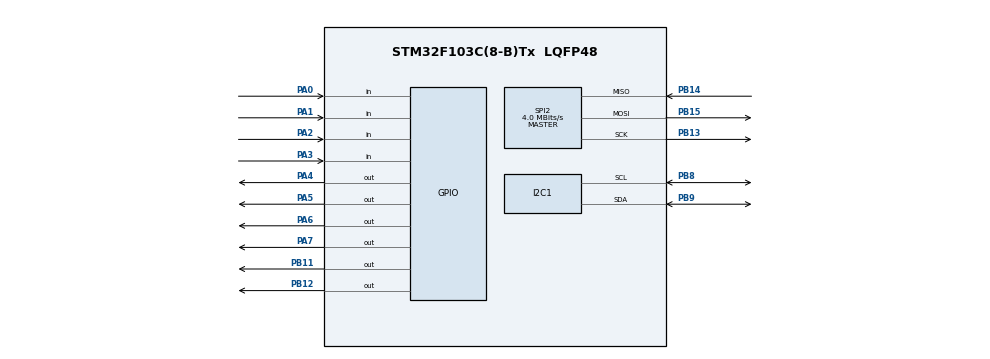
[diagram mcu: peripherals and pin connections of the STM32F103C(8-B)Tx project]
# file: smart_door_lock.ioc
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Mcu.Family=STM32F1
Mcu.Name=STM32F103C(8-B)Tx
Mcu.Package=LQFP48
NVIC.PriorityGroup=NVIC_PRIORITYGROUP_4
PA0-WKUP.GPIO_PuPd=GPIO_PULLUP
PA0-WKUP.Signal=GPIO_Input
PA1.GPIO_PuPd=GPIO_PULLUP
PA1.Signal=GPIO_Input
PA13.Mode=Serial_Wire
PA13.Signal=SYS_JTMS-SWDIO
PA14.Mode=Serial_Wire
PA14.Signal=SYS_JTCK-SWCLK
PA2.GPIO_PuPd=GPIO_PULLUP
PA2.Signal=GPIO_Input
PA3.GPIO_PuPd=GPIO_PULLUP
PA3.Signal=GPIO_Input
PA4.GPIO_PuPd=GPIO_PULLUP
PA4.Signal=GPIO_Output
PA5.GPIO_PuPd=GPIO_PULLUP
PA5.Signal=GPIO_Output
PA6.GPIO_PuPd=GPIO_PULLUP
PA6.Signal=GPIO_Output
PA7.GPIO_PuPd=GPIO_PULLUP
PA7.Signal=GPIO_Output
PB11.GPIO_PuPd=GPIO_PULLUP
PB11.Signal=GPIO_Output
PB12.Signal=GPIO_Output
PB13.Mode=Full_Duplex_Master
PB13.Signal=SPI2_SCK
PB14.Mode=Full_Duplex_Master
PB14.Signal=SPI2_MISO
PB15.Mode=Full_Duplex_Master
PB15.Signal=SPI2_MOSI
PB8.Mode=I2C
PB8.Signal=I2C1_SCL
PB9.Mode=I2C
PB9.Signal=I2C1_SDA
PD0-OSC_IN.Mode=HSE-External-Oscillator
PD0-OSC_IN.Signal=RCC_OSC_IN
PD1-OSC_OUT.Mode=HSE-External-Oscillator
PD1-OSC_OUT.Signal=RCC_OSC_OUT
ProjectManager.HeapSize=0x200
ProjectManager.StackSize=0x400
ProjectManager.TargetToolchain=STM32CubeIDE
RCC.APB1Freq_Value=8000000
RCC.APB2Freq_Value=8000000
SPI2.BaudRatePrescaler=SPI_BAUDRATEPRESCALER_2
SPI2.CLKPhase=SPI_PHASE_2EDGE
SPI2.CLKPolarity=SPI_POLARITY_HIGH
SPI2.CRCCalculation=SPI_CRCCALCULATION_DISABLE
SPI2.CalculateBaudRate=4.0 MBits/s
SPI2.DataSize=SPI_DATASIZE_8BIT
SPI2.Direction=SPI_DIRECTION_2LINES
SPI2.Mode=SPI_MODE_MASTER
SPI2.VirtualType=VM_MASTER
board=custom

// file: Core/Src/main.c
/* USER CODE BEGIN Header */
/**
  ******************************************************************************
  * @file           : main.c
  * @brief          : Main program body
  ******************************************************************************
  * @attention
  *
  * Copyright (c) 2023 STMicroelectronics.
  * All rights reserved.
  *
  * This software is licensed under terms that can be found in the LICENSE file
  * in the root directory of this software component.
  * If no LICENSE file comes with this software, it is provided AS-IS.
  *
  ******************************************************************************
  */
/* USER CODE END Header */
#include "main.h"

/* USER CODE BEGIN Includes */
#include "application.h"
/* USER CODE END Includes */

I2C_HandleTypeDef hi2c1;

SPI_HandleTypeDef hspi2;

void SystemClock_Config(void);
static void MX_GPIO_Init(void);
static void MX_SPI2_Init(void);
static void MX_I2C1_Init(void);

int main(void)
{

  /* MCU Configuration--------------------------------------------------------*/

  /* Reset of all peripherals, Initializes the Flash interface and the Systick. */
  HAL_Init();

  /* Configure the system clock */
  SystemClock_Config();

  /* Initialize all configured peripherals */
  MX_GPIO_Init();
  MX_SPI2_Init();
  MX_I2C1_Init();

  /* Infinite loop */
  while (1)
  {

    /* USER CODE BEGIN 3 */
	 app_loop(&hspi2, &hi2c1);
  }
  /* USER CODE END 3 */
}

void SystemClock_Config(void)
{
  RCC_OscInitTypeDef RCC_OscInitStruct = {0};
  RCC_ClkInitTypeDef RCC_ClkInitStruct = {0};

  /** Initializes the RCC Oscillators according to the specified parameters
  * in the RCC_OscInitTypeDef structure.
  */
  RCC_OscInitStruct.OscillatorType = RCC_OSCILLATORTYPE_HSI;
  RCC_OscInitStruct.HSIState = RCC_HSI_ON;
  RCC_OscInitStruct.HSICalibrationValue = RCC_HSICALIBRATION_DEFAULT;
  RCC_OscInitStruct.PLL.PLLState = RCC_PLL_NONE;
  if (HAL_RCC_OscConfig(&RCC_OscInitStruct) != HAL_OK)
  {
    Error_Handler();
  }

  /** Initializes the CPU, AHB and APB buses clocks
  */
  RCC_ClkInitStruct.ClockType = RCC_CLOCKTYPE_HCLK|RCC_CLOCKTYPE_SYSCLK
                              |RCC_CLOCKTYPE_PCLK1|RCC_CLOCKTYPE_PCLK2;
  RCC_ClkInitStruct.SYSCLKSource = RCC_SYSCLKSOURCE_HSI;
  RCC_ClkInitStruct.AHBCLKDivider = RCC_SYSCLK_DIV1;
  RCC_ClkInitStruct.APB1CLKDivider = RCC_HCLK_DIV1;
  RCC_ClkInitStruct.APB2CLKDivider = RCC_HCLK_DIV1;

  if (HAL_RCC_ClockConfig(&RCC_ClkInitStruct, FLASH_LATENCY_0) != HAL_OK)
  {
    Error_Handler();
  }
}

static void MX_I2C1_Init(void)
{

  hi2c1.Instance = I2C1;
  hi2c1.Init.ClockSpeed = 100000;
  hi2c1.Init.DutyCycle = I2C_DUTYCYCLE_2;
  hi2c1.Init.OwnAddress1 = 0;
  hi2c1.Init.AddressingMode = I2C_ADDRESSINGMODE_7BIT;
  hi2c1.Init.DualAddressMode = I2C_DUALADDRESS_DISABLE;
  hi2c1.Init.OwnAddress2 = 0;
  hi2c1.Init.GeneralCallMode = I2C_GENERALCALL_DISABLE;
  hi2c1.Init.NoStretchMode = I2C_NOSTRETCH_DISABLE;
  if (HAL_I2C_Init(&hi2c1) != HAL_OK)
  {
    Error_Handler();
  }

}

static void MX_SPI2_Init(void)
{

  /* SPI2 parameter configuration*/
  hspi2.Instance = SPI2;
  hspi2.Init.Mode = SPI_MODE_MASTER;
  hspi2.Init.Direction = SPI_DIRECTION_2LINES;
  hspi2.Init.DataSize = SPI_DATASIZE_8BIT;
  hspi2.Init.CLKPolarity = SPI_POLARITY_HIGH;
  hspi2.Init.CLKPhase = SPI_PHASE_2EDGE;
  hspi2.Init.NSS = SPI_NSS_SOFT;
  hspi2.Init.BaudRatePrescaler = SPI_BAUDRATEPRESCALER_2;
  hspi2.Init.FirstBit = SPI_FIRSTBIT_MSB;
  hspi2.Init.TIMode = SPI_TIMODE_DISABLE;
  hspi2.Init.CRCCalculation = SPI_CRCCALCULATION_DISABLE;
  hspi2.Init.CRCPolynomial = 10;
  if (HAL_SPI_Init(&hspi2) != HAL_OK)
  {
    Error_Handler();
  }

}

static void MX_GPIO_Init(void)
{
  GPIO_InitTypeDef GPIO_InitStruct = {0};

  /* GPIO Ports Clock Enable */
  __HAL_RCC_GPIOD_CLK_ENABLE();
  __HAL_RCC_GPIOA_CLK_ENABLE();
  __HAL_RCC_GPIOB_CLK_ENABLE();

  /*Configure GPIO pin Output Level */
  HAL_GPIO_WritePin(GPIOA, GPIO_PIN_4|GPIO_PIN_5|GPIO_PIN_6|GPIO_PIN_7, GPIO_PIN_RESET);

  /*Configure GPIO pin Output Level */
  HAL_GPIO_WritePin(GPIOB, GPIO_PIN_11|GPIO_PIN_12, GPIO_PIN_RESET);

  /*Configure GPIO pins : PA0 PA1 PA2 PA3 */
  GPIO_InitStruct.Pin = GPIO_PIN_0|GPIO_PIN_1|GPIO_PIN_2|GPIO_PIN_3;
  GPIO_InitStruct.Mode = GPIO_MODE_INPUT;
  GPIO_InitStruct.Pull = GPIO_PULLUP;
  HAL_GPIO_Init(GPIOA, &GPIO_InitStruct);

  /*Configure GPIO pins : PA4 PA5 PA6 PA7 */
  GPIO_InitStruct.Pin = GPIO_PIN_4|GPIO_PIN_5|GPIO_PIN_6|GPIO_PIN_7;
  GPIO_InitStruct.Mode = GPIO_MODE_OUTPUT_PP;
  GPIO_InitStruct.Pull = GPIO_PULLUP;
  GPIO_InitStruct.Speed = GPIO_SPEED_FREQ_LOW;
  HAL_GPIO_Init(GPIOA, &GPIO_InitStruct);

  /*Configure GPIO pin : PB11 */
  GPIO_InitStruct.Pin = GPIO_PIN_11;
  GPIO_InitStruct.Mode = GPIO_MODE_OUTPUT_PP;
  GPIO_InitStruct.Pull = GPIO_PULLUP;
  GPIO_InitStruct.Speed = GPIO_SPEED_FREQ_LOW;
  HAL_GPIO_Init(GPIOB, &GPIO_InitStruct);

  /*Configure GPIO pin : PB12 */
  GPIO_InitStruct.Pin = GPIO_PIN_12;
  GPIO_InitStruct.Mode = GPIO_MODE_OUTPUT_PP;
  GPIO_InitStruct.Pull = GPIO_NOPULL;
  GPIO_InitStruct.Speed = GPIO_SPEED_FREQ_LOW;
  HAL_GPIO_Init(GPIOB, &GPIO_InitStruct);

}

void Error_Handler(void)
{
  __disable_irq();
  while (1)
  {
  }
}
